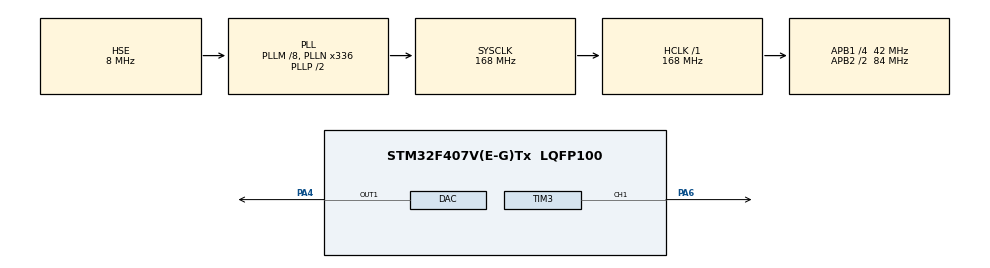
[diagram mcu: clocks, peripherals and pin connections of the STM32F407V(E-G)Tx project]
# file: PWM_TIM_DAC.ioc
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Mcu.Family=STM32F4
Mcu.Name=STM32F407V(E-G)Tx
Mcu.Package=LQFP100
NVIC.PriorityGroup=NVIC_PRIORITYGROUP_0
NVIC.TIM3_IRQn=true\:0\:0\:false\:false\:true\:true\:true\:true
PA4.Signal=COMP_DAC1_group
PA6.Signal=S_TIM3_CH1
PC14-OSC32_IN.Mode=LSE-External-Oscillator
PC14-OSC32_IN.Signal=RCC_OSC32_IN
PC15-OSC32_OUT.Mode=LSE-External-Oscillator
PC15-OSC32_OUT.Signal=RCC_OSC32_OUT
PH0-OSC_IN.Mode=HSE-External-Oscillator
PH0-OSC_IN.Signal=RCC_OSC_IN
PH1-OSC_OUT.Mode=HSE-External-Oscillator
PH1-OSC_OUT.Signal=RCC_OSC_OUT
ProjectManager.HeapSize=0x200
ProjectManager.StackSize=0x400
ProjectManager.TargetToolchain=STM32CubeIDE
RCC.48MHZClocksFreq_Value=48000000
RCC.AHBFreq_Value=168000000
RCC.APB1CLKDivider=RCC_HCLK_DIV4
RCC.APB1Freq_Value=42000000
RCC.APB1TimFreq_Value=84000000
RCC.APB2CLKDivider=RCC_HCLK_DIV2
RCC.APB2Freq_Value=84000000
RCC.APB2TimFreq_Value=168000000
RCC.CortexFreq_Value=168000000
RCC.HCLKFreq_Value=168000000
RCC.HSE_VALUE=8000000
RCC.HSI_VALUE=16000000
RCC.PLLM=8
RCC.PLLN=336
RCC.PLLQ=7
RCC.PLLSourceVirtual=RCC_PLLSOURCE_HSE
RCC.SYSCLKFreq_VALUE=168000000
RCC.SYSCLKSource=RCC_SYSCLKSOURCE_PLLCLK
RCC.VCOOutputFreq_Value=336000000
SH.COMP_DAC1_group.0=DAC_OUT1,DAC_OUT1
SH.S_TIM3_CH1.0=TIM3_CH1,PWM Generation1 CH1
TIM3.Channel-PWM\ Generation1\ CH1=TIM_CHANNEL_1
TIM3.CounterMode=TIM_COUNTERMODE_DOWN
TIM3.Period=\ 999
TIM3.Prescaler=83
TIM3.Pulse-PWM\ Generation1\ CH1=500
VP_TIM3_VS_ClockSourceINT.Mode=Internal
board=STM32F407G-DISC1

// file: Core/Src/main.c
/* USER CODE BEGIN Header */
/**
  ******************************************************************************
  * @file           : main.c
  * @brief          : Main program body
  ******************************************************************************
  * @attention
  *
  * Copyright (c) 2023 STMicroelectronics.
  * All rights reserved.
  *
  * This software is licensed under terms that can be found in the LICENSE file
  * in the root directory of this software component.
  * If no LICENSE file comes with this software, it is provided AS-IS.
  *
  ******************************************************************************
  */
/* USER CODE END Header */
#include "main.h"

 DAC_HandleTypeDef hdac;

TIM_HandleTypeDef htim3;

void SystemClock_Config(void);
static void MX_GPIO_Init(void);
static void MX_DAC_Init(void);
static void MX_TIM3_Init(void);

int main(void)
{

  /* MCU Configuration--------------------------------------------------------*/

  /* Reset of all peripherals, Initializes the Flash interface and the Systick. */
  HAL_Init();

  /* Configure the system clock */
  SystemClock_Config();

  /* Initialize all configured peripherals */
  MX_GPIO_Init();
  MX_DAC_Init();
  MX_TIM3_Init();
  /* USER CODE BEGIN 2 */
HAL_DAC_Start(&hdac, DAC_CHANNEL_1);
HAL_TIM_Base_Start(&htim3);
HAL_TIM_PWM_Start(&htim3, TIM_CHANNEL_1);
  /* USER CODE END 2 */

  /* Infinite loop */
  while (1)
  {

  }
}

void SystemClock_Config(void)
{
  RCC_OscInitTypeDef RCC_OscInitStruct = {0};
  RCC_ClkInitTypeDef RCC_ClkInitStruct = {0};

  /** Configure the main internal regulator output voltage
  */
  __HAL_RCC_PWR_CLK_ENABLE();
  __HAL_PWR_VOLTAGESCALING_CONFIG(PWR_REGULATOR_VOLTAGE_SCALE1);

  /** Initializes the RCC Oscillators according to the specified parameters
  * in the RCC_OscInitTypeDef structure.
  */
  RCC_OscInitStruct.OscillatorType = RCC_OSCILLATORTYPE_HSE;
  RCC_OscInitStruct.HSEState = RCC_HSE_ON;
  RCC_OscInitStruct.PLL.PLLState = RCC_PLL_ON;
  RCC_OscInitStruct.PLL.PLLSource = RCC_PLLSOURCE_HSE;
  RCC_OscInitStruct.PLL.PLLM = 8;
  RCC_OscInitStruct.PLL.PLLN = 336;
  RCC_OscInitStruct.PLL.PLLP = RCC_PLLP_DIV2;
  RCC_OscInitStruct.PLL.PLLQ = 7;
  if (HAL_RCC_OscConfig(&RCC_OscInitStruct) != HAL_OK)
  {
    Error_Handler();
  }

  /** Initializes the CPU, AHB and APB buses clocks
  */
  RCC_ClkInitStruct.ClockType = RCC_CLOCKTYPE_HCLK|RCC_CLOCKTYPE_SYSCLK
                              |RCC_CLOCKTYPE_PCLK1|RCC_CLOCKTYPE_PCLK2;
  RCC_ClkInitStruct.SYSCLKSource = RCC_SYSCLKSOURCE_PLLCLK;
  RCC_ClkInitStruct.AHBCLKDivider = RCC_SYSCLK_DIV1;
  RCC_ClkInitStruct.APB1CLKDivider = RCC_HCLK_DIV4;
  RCC_ClkInitStruct.APB2CLKDivider = RCC_HCLK_DIV2;

  if (HAL_RCC_ClockConfig(&RCC_ClkInitStruct, FLASH_LATENCY_5) != HAL_OK)
  {
    Error_Handler();
  }
}

static void MX_DAC_Init(void)
{

  DAC_ChannelConfTypeDef sConfig = {0};

  /** DAC Initialization
  */
  hdac.Instance = DAC;
  if (HAL_DAC_Init(&hdac) != HAL_OK)
  {
    Error_Handler();
  }

  /** DAC channel OUT1 config
  */
  sConfig.DAC_Trigger = DAC_TRIGGER_NONE;
  sConfig.DAC_OutputBuffer = DAC_OUTPUTBUFFER_ENABLE;
  if (HAL_DAC_ConfigChannel(&hdac, &sConfig, DAC_CHANNEL_1) != HAL_OK)
  {
    Error_Handler();
  }

}

static void MX_TIM3_Init(void)
{

  TIM_ClockConfigTypeDef sClockSourceConfig = {0};
  TIM_MasterConfigTypeDef sMasterConfig = {0};
  TIM_OC_InitTypeDef sConfigOC = {0};

  htim3.Instance = TIM3;
  htim3.Init.Prescaler = 83;
  htim3.Init.CounterMode = TIM_COUNTERMODE_DOWN;
  htim3.Init.Period = 999;
  htim3.Init.ClockDivision = TIM_CLOCKDIVISION_DIV1;
  htim3.Init.AutoReloadPreload = TIM_AUTORELOAD_PRELOAD_DISABLE;
  if (HAL_TIM_Base_Init(&htim3) != HAL_OK)
  {
    Error_Handler();
  }
  sClockSourceConfig.ClockSource = TIM_CLOCKSOURCE_INTERNAL;
  if (HAL_TIM_ConfigClockSource(&htim3, &sClockSourceConfig) != HAL_OK)
  {
    Error_Handler();
  }
  if (HAL_TIM_PWM_Init(&htim3) != HAL_OK)
  {
    Error_Handler();
  }
  sMasterConfig.MasterOutputTrigger = TIM_TRGO_RESET;
  sMasterConfig.MasterSlaveMode = TIM_MASTERSLAVEMODE_DISABLE;
  if (HAL_TIMEx_MasterConfigSynchronization(&htim3, &sMasterConfig) != HAL_OK)
  {
    Error_Handler();
  }
  sConfigOC.OCMode = TIM_OCMODE_PWM1;
  sConfigOC.Pulse = 300;
  sConfigOC.OCPolarity = TIM_OCPOLARITY_HIGH;
  sConfigOC.OCFastMode = TIM_OCFAST_DISABLE;
  if (HAL_TIM_PWM_ConfigChannel(&htim3, &sConfigOC, TIM_CHANNEL_1) != HAL_OK)
  {
    Error_Handler();
  }
  HAL_TIM_MspPostInit(&htim3);

}

static void MX_GPIO_Init(void)
{

  /* GPIO Ports Clock Enable */
  __HAL_RCC_GPIOC_CLK_ENABLE();
  __HAL_RCC_GPIOH_CLK_ENABLE();
  __HAL_RCC_GPIOA_CLK_ENABLE();

}

void Error_Handler(void)
{
  __disable_irq();
  while (1)
  {
  }
}
